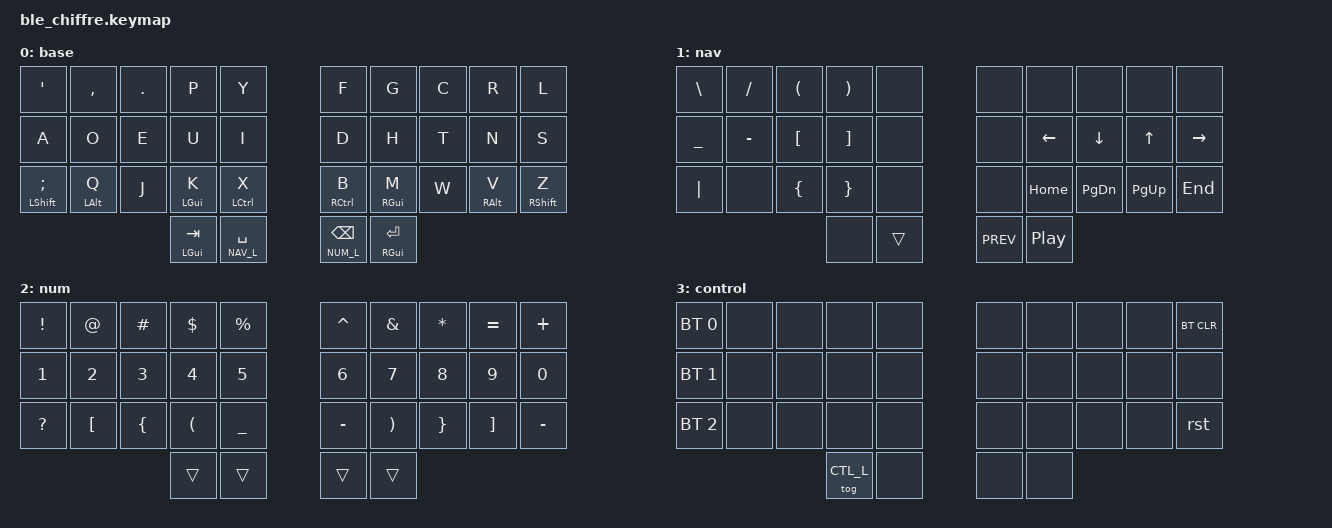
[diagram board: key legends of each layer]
/*
 * Copyright (c) 2020 The ZMK Contributors
 *
 * SPDX-License-Identifier: MIT
 */

#include <behaviors.dtsi>
#include <dt-bindings/zmk/keys.h>
#include <dt-bindings/zmk/bt.h>
#include <dt-bindings/zmk/rgb.h>

#define BASE_L  0
#define NAV_L   1
#define NUM_L   2
#define CTL_L   3

&lt { quick_tap_ms = <200>; };

/ {
    behaviors {
        hm: bottomrow_mods {
            compatible = "zmk,behavior-hold-tap";
            label = "Bottom Row Mods";
            #binding-cells = <2>;
            tapping_term_ms = <240>;
            quick_tap_ms = <200>;
            flavor = "tap-preferred";
            bindings = <&kp>, <&kp>;
        };
        la: layer_taps {
            compatible = "zmk,behavior-hold-tap";
            label = "Layer tap";
            #binding-cells = <2>;
            tapping_term_ms = <215>;
            quick_tap_ms = <200>;
            flavor = "tap-preferred";
            bindings = <&mo>, <&kp>;
        };
        sp: space_layer_caps {
            compatible = "zmk,behavior-hold-tap";
            label = "Super space";
            #binding-cells = <2>;
            tapping_term_ms = <200>;
            quick_tap_ms = <0>;
            flavor = "tap-preferred";
            bindings = <&mo>, <&spc_cwd>;
        };

        spc_cwd: space_caps {
            compatible = "zmk,behavior-mod-morph";
            label = "Shift+Space > Caps Word";
            #binding-cells = <0>;
            bindings = <&kp SPACE>, <&caps_word>;
            mods = <(RSHFT|LSHFT)>;
        };
        qot_swt: quote_switch {
            compatible = "zmk,behavior-mod-morph";
            label = "Quote, or app switch";
            #binding-cells = <0>;
            bindings = <&kp APOS>, <&kp TAB>;
            mods = <(LGUI)>;
        };

        rst: boot_reset {
            compatible = "zmk,behavior-hold-tap";
            label = "Bootloader Tap - Reset Hold";
            #binding-cells = <2>;
            tapping_term_ms = <200>;
            flavor = "balanced";
            bindings = <&reset>, <&bootloader>;
        };
    };
};

/ {
    combos {
        compatible = "zmk,combos";
        combo_enter {
            timeout-ms = <60>;
            key-positions = <8 9>;
            bindings = <&kp RET>;
        };
        combo_esc {
            timeout-ms = <60>;
            key-positions = <0 1>;
            bindings = <&kp ESC>;
        };
        combo_grave {
            timeout-ms = <40>;
            key-positions = <1 2>;
            bindings = <&kp GRAVE>;
        };
        combo_tab {
            timeout-ms = <60>;
            key-positions = <10 11>;
            bindings = <&kp TAB>;
        };

        combo_control_layer {
            timeout-ms = <80>;
            key-positions = <4 5 24 25>;
            layers = <BASE_L CTL_L>;
            bindings = <&tog CTL_L>;
        };
    };
}; 

/ {
    keymap {
        compatible = "zmk,keymap";

        base {
            bindings = <
    &kp APOS       &kp COMMA    &kp DOT     &kp P        &kp Y           &kp F          &kp G        &kp C       &kp R       &kp L
    &kp A          &kp O        &kp E       &kp U        &kp I           &kp D          &kp H        &kp T       &kp N       &kp S
    &hm LSHFT SEMI &hm LALT Q   &kp J       &hm LGUI K   &hm LCTRL X     &hm RCTRL B    &hm RGUI M   &kp W       &hm RALT V  &hm RSHFT Z
                                            &hm LGUI TAB &lt NAV_L SPACE &lt NUM_L BSPC &hm RGUI RET
            >;
        };

        nav {
            bindings = <
    &kp BSLH    &kp FSLH    &kp LPAR    &kp RPAR    &none        &none       &none       &none       &none       &none
    &kp UNDER   &kp MINUS   &kp LBKT    &kp RBKT    &none        &none       &kp LEFT    &kp DOWN    &kp UP      &kp RIGHT
    &kp PIPE    &none       &kp LBRC    &kp RBRC    &none        &none       &kp HOME    &kp PG_DN   &kp PG_UP   &kp END
                                        &none       &trans       &kp C_PREV  &kp C_PP
            >;
        };

        num {
            bindings = <
    &kp EXCL    &kp AT      &kp POUND   &kp DLLR    &kp PRCNT    &kp CARET   &kp AMPS    &kp STAR    &kp EQUAL    &kp PLUS
    &kp N1      &kp N2      &kp N3      &kp N4      &kp N5       &kp N6      &kp N7      &kp N8      &kp N9      &kp N0
    &kp QMARK   &kp LBKT    &kp LBRC    &kp LPAR    &kp UNDER    &kp MINUS   &kp RPAR    &kp RBRC    &kp RBKT    &kp MINUS
                                        &trans      &trans       &trans      &trans
            >;
        };

        control {
            bindings = <
    &bt BT_SEL 0 &none       &none       &none       &none       &none       &none       &none       &none       &bt BT_CLR
    &bt BT_SEL 1 &none       &none       &none       &none       &none       &none       &none       &none       &none
    &bt BT_SEL 2 &none       &none       &none       &none       &none       &none       &none       &none       &rst
                                         &tog CTL_L  &none       &none       &none
            >;
        };
    };
};
